# FAKE_MCU register map
Vendor: Jetbrains; Series: FAKE_MCU; File version: 1.0
Fake device peripherals definition for testing purposes
CPU: CM3 r1p1, little endian, no MPU, no FPU, 4 interrupt priority bits
Registers are 32-bit, read-write, reset 0x4 unless marked. A register's access mark holds for its fields unless they carry their own. Offsets are from the block's base; lines under a group give offsets from that group; [hi:lo] are bit positions; {n}, {i} and the like mark numbered series; 'fields as' and 'values as' point back to an identical list; <NAME> marks a mode.

## Memory map
0x20001800 FAKE_PERIPH size 0x10 — Fake device peripherals definition for testing purposes

## FAKE_PERIPH — Fake device peripherals definition for testing purposes
Base 0x20001800
0x00 REG_8 8-bit — 8-bit Register
0x01 REG_16 16-bit reset 0x5 — 16-bit Register
0x03 REG_32 reset 0x6 — 32-bit Register
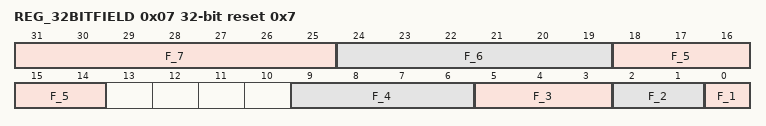
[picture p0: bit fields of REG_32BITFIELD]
0x07 REG_32BITFIELD reset 0x7 — 32-bit Register with bit fields
  [31:25] F_7 — 7-bit field
  [24:19] F_6 — 6-bit field
  [18:14] F_5 — 5-bit field
  [9:6] F_4 — 4-bit field
  [5:3] F_3 — 3-bit field
  [2:1] F_2 — 2-bit field
  [0] F_1 — 1-bit field
0x10 REG_TEST_FIELD_BITNESS_AND_BITMASKS 64-bit reset 0x0 (reset mask 0xFFFFFFFF)
  [63:0] BIT_64_FIELD
    other=DEF_VALUE; 0xFFFFFFFFFFFFFFFF=MINUS_ONE (All bits == 1); 0b0xx1x1=5_OR_13_OR_21 (Test bitmask with a "do not care" bit)

## Licence text in the file
This is free and unencumbered software released into the public domain. Anyone is free to copy, modify, publish, use, compile, sell, or distribute this software, either in source code form or as a compiled binary, for any purpose, commercial or non-commercial, and by any means. In jurisdictions that recognize copyright laws, the author or authors of this software dedicate any and all copyright interest in the software to the public domain. We make this dedication for the benefit of the public at large and to the detriment of our heirs and successors. We intend this dedication to be an overt act of relinquishment in perpetuity of all present and future rights to this software under copyright law. THE SOFTWARE IS PROVIDED "AS IS", WITHOUT WARRANTY OF ANY KIND, EXPRESS OR IMPLIED, INCLUDING BUT NOT LIMITED TO THE WARRANTIES OF MERCHANTABILITY, FITNESS FOR A PARTICULAR PURPOSE AND NONINFRINGEMENT. IN NO EVENT SHALL THE AUTHORS BE LIABLE FOR ANY CLAIM, DAMAGES OR OTHER LIABILITY, WHETHER IN AN ACTION OF CONTRACT, TORT OR OTHERWISE, ARISING FROM, OUT OF OR IN CONNECTION WITH THE SOFTWARE OR THE USE OR OTHER DEALINGS IN THE SOFTWARE. For more information, please refer to http://unlicense.org/
